VERSION ""

NS_ :

BS_:

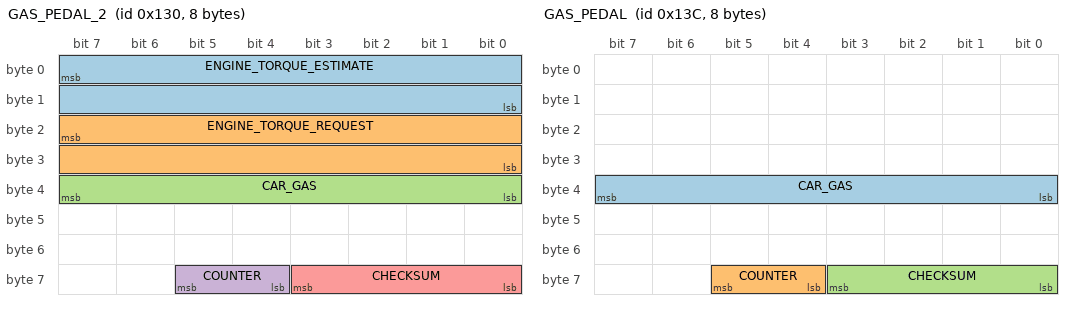
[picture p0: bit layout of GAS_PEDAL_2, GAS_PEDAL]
BO_ 304 GAS_PEDAL_2: 8 PCM
 SG_ ENGINE_TORQUE_ESTIMATE : 7|16@0- (1,0) [-1000|1000] "Nm" EON
 SG_ ENGINE_TORQUE_REQUEST : 23|16@0- (1,0) [-1000|1000] "Nm" EON
 SG_ CAR_GAS : 39|8@0+ (1,0) [0|255] "" EON
 SG_ COUNTER : 61|2@0+ (1,0) [0|3] "" EON
 SG_ CHECKSUM : 59|4@0+ (1,0) [0|15] "" EON

BO_ 316 GAS_PEDAL: 8 PCM
 SG_ CAR_GAS : 39|8@0+ (1,0) [0|255] "" EON
 SG_ COUNTER : 61|2@0+ (1,0) [0|3] "" EON
 SG_ CHECKSUM : 59|4@0+ (1,0) [0|15] "" EON

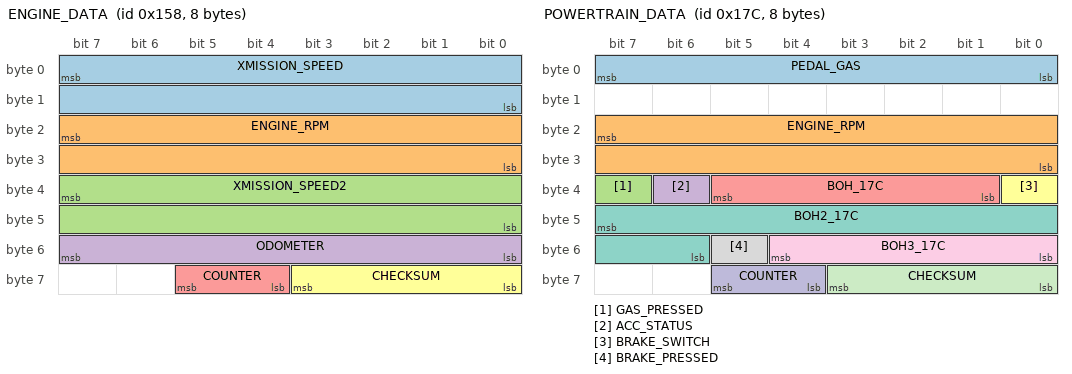
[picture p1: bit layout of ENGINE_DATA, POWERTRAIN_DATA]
BO_ 344 ENGINE_DATA: 8 PCM
 SG_ XMISSION_SPEED : 7|16@0+ (0.01,0) [0|250] "kph" EON
 SG_ ENGINE_RPM : 23|16@0+ (1,0) [0|15000] "rpm" EON
 SG_ XMISSION_SPEED2 : 39|16@0+ (0.01,0) [0|250] "kph" EON
 SG_ ODOMETER : 55|8@0+ (10,0) [0|2550] "m" XXX
 SG_ COUNTER : 61|2@0+ (1,0) [0|3] "" EON
 SG_ CHECKSUM : 59|4@0+ (1,0) [0|15] "" EON

BO_ 380 POWERTRAIN_DATA: 8 PCM
 SG_ PEDAL_GAS : 7|8@0+ (1,0) [0|255] "" EON
 SG_ ENGINE_RPM : 23|16@0+ (1,0) [0|15000] "rpm" EON
 SG_ GAS_PRESSED : 39|1@0+ (1,0) [0|1] "" EON
 SG_ ACC_STATUS : 38|1@0+ (1,0) [0|1] "" EON
 SG_ BOH_17C : 37|5@0+ (1,0) [0|1] "" EON
 SG_ BRAKE_SWITCH : 32|1@0+ (1,0) [0|1] "" EON
 SG_ BOH2_17C : 47|10@0+ (1,0) [0|1] "" EON
 SG_ BRAKE_PRESSED : 53|1@0+ (1,0) [0|1] "" EON
 SG_ BOH3_17C : 52|5@0+ (1,0) [0|1] "" EON
 SG_ COUNTER : 61|2@0+ (1,0) [0|3] "" EON
 SG_ CHECKSUM : 59|4@0+ (1,0) [0|15] "" EON

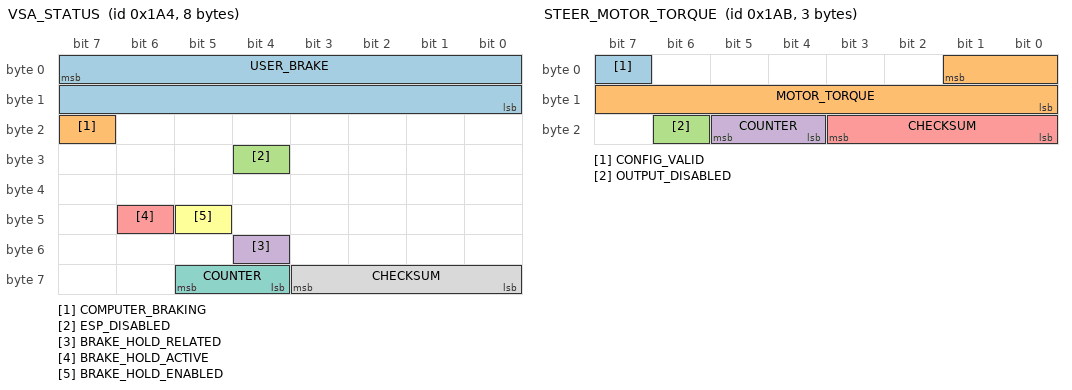
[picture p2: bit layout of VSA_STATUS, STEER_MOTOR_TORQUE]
BO_ 420 VSA_STATUS: 8 VSA
 SG_ USER_BRAKE : 7|16@0+ (0.015625,-1.609375) [0|1000] "" EON
 SG_ COMPUTER_BRAKING : 23|1@0+ (1,0) [0|1] "" EON
 SG_ ESP_DISABLED : 28|1@0+ (1,0) [0|1] "" EON
 SG_ BRAKE_HOLD_RELATED : 52|1@0+ (1,0) [0|1] "" XXX
 SG_ BRAKE_HOLD_ACTIVE : 46|1@0+ (1,0) [0|1] "" EON
 SG_ BRAKE_HOLD_ENABLED : 45|1@0+ (1,0) [0|1] "" EON
 SG_ COUNTER : 61|2@0+ (1,0) [0|3] "" EON
 SG_ CHECKSUM : 59|4@0+ (1,0) [0|15] "" EON

BO_ 427 STEER_MOTOR_TORQUE: 3 EPS
 SG_ CONFIG_VALID : 7|1@0+ (1,0) [0|1] "" EON
 SG_ MOTOR_TORQUE : 1|10@0+ (1,0) [0|256] "" EON
 SG_ OUTPUT_DISABLED : 22|1@0+ (1,0) [0|1] "" EON
 SG_ COUNTER : 21|2@0+ (1,0) [0|3] "" EON
 SG_ CHECKSUM : 19|4@0+ (1,0) [0|15] "" EON

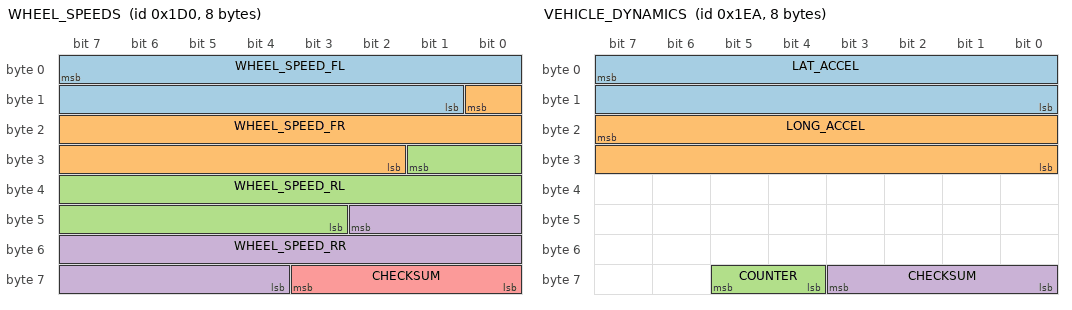
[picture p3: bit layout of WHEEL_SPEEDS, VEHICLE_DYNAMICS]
BO_ 464 WHEEL_SPEEDS: 8 VSA
 SG_ WHEEL_SPEED_FL : 7|15@0+ (0.01,0) [0|250] "kph" EON
 SG_ WHEEL_SPEED_FR : 8|15@0+ (0.01,0) [0|250] "kph" EON
 SG_ WHEEL_SPEED_RL : 25|15@0+ (0.01,0) [0|250] "kph" EON
 SG_ WHEEL_SPEED_RR : 42|15@0+ (0.01,0) [0|250] "kph" EON
 SG_ CHECKSUM : 59|4@0+ (1,0) [0|3] "" EON

BO_ 490 VEHICLE_DYNAMICS: 8 VSA
 SG_ LAT_ACCEL : 7|16@0- (0.0015,0) [-20|20] "m/s2" EON
 SG_ LONG_ACCEL : 23|16@0- (0.0015,0) [-20|20] "m/s2" EON
 SG_ COUNTER : 61|2@0+ (1,0) [0|3] "" EON
 SG_ CHECKSUM : 59|4@0+ (1,0) [0|3] "" EON

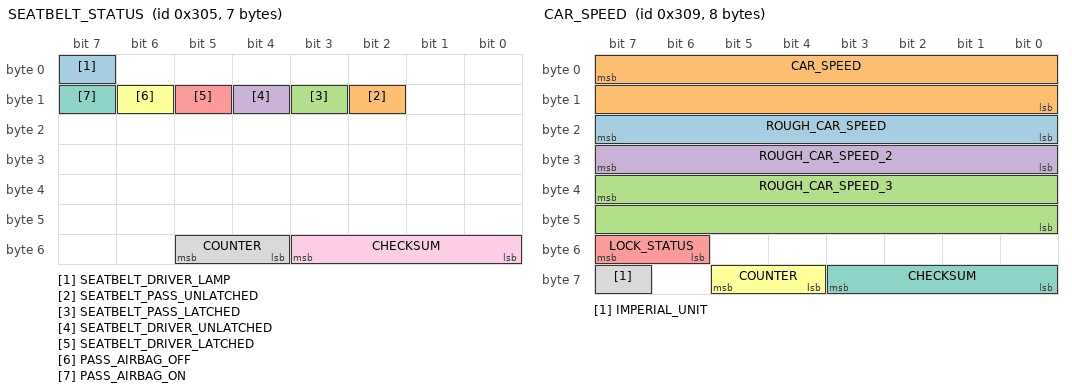
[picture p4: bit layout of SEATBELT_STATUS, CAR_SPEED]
BO_ 773 SEATBELT_STATUS: 7 BDY
 SG_ SEATBELT_DRIVER_LAMP : 7|1@0+ (1,0) [0|1] "" EON
 SG_ SEATBELT_PASS_UNLATCHED : 10|1@0+ (1,0) [0|1] "" EON
 SG_ SEATBELT_PASS_LATCHED : 11|1@0+ (1,0) [0|1] "" EON
 SG_ SEATBELT_DRIVER_UNLATCHED : 12|1@0+ (1,0) [0|1] "" EON
 SG_ SEATBELT_DRIVER_LATCHED : 13|1@0+ (1,0) [0|1] "" EON
 SG_ PASS_AIRBAG_OFF : 14|1@0+ (1,0) [0|1] "" EON
 SG_ PASS_AIRBAG_ON : 15|1@0+ (1,0) [0|1] "" EON
 SG_ COUNTER : 53|2@0+ (1,0) [0|3] "" EON
 SG_ CHECKSUM : 51|4@0+ (1,0) [0|3] "" EON

BO_ 777 CAR_SPEED: 8 PCM
 SG_ ROUGH_CAR_SPEED : 23|8@0+ (1,0) [0|255] "mph" XXX
 SG_ CAR_SPEED : 7|16@0+ (0.01,0) [0|65535] "kph" XXX
 SG_ ROUGH_CAR_SPEED_3 : 39|16@0+ (0.01,0) [0|65535] "kph" XXX
 SG_ ROUGH_CAR_SPEED_2 : 31|8@0+ (1,0) [0|255] "mph" XXX
 SG_ LOCK_STATUS : 55|2@0+ (1,0) [0|255] "" XXX
 SG_ COUNTER : 61|2@0+ (1,0) [0|3] "" XXX
 SG_ CHECKSUM : 59|4@0+ (1,0) [0|15] "" XXX
 SG_ IMPERIAL_UNIT : 63|1@0+ (1,0) [0|1] "" XXX

BO_ 780 ACC_HUD: 8 ADAS
 SG_ PCM_SPEED : 7|16@0+ (0.01,0) [0|250] "kph" BDY
 SG_ PCM_GAS : 23|8@0+ (1,0) [0|127] "" BDY
 SG_ CRUISE_SPEED : 31|8@0+ (1,0) [0|255] "kph" BDY
 SG_ DTC_MODE : 39|1@0+ (1,0) [0|1] "" BDY
 SG_ BOH : 38|1@0+ (1,0) [0|1] "" BDY
 SG_ ACC_PROBLEM : 37|1@0+ (1,0) [0|1] "" BDY
 SG_ FCM_OFF : 35|1@0+ (1,0) [0|1] "" BDY
 SG_ FCM_OFF_2 : 36|1@0+ (1,0) [0|1] "" BDY
 SG_ FCM_PROBLEM : 34|1@0+ (1,0) [0|1] "" BDY
 SG_ RADAR_OBSTRUCTED : 33|1@0+ (1,0) [0|1] "" BDY
 SG_ ENABLE_MINI_CAR : 32|1@0+ (1,0) [0|1] "" BDY
 SG_ HUD_DISTANCE : 47|2@0+ (1,0) [0|3] "" BDY
 SG_ HUD_LEAD : 45|2@0+ (1,0) [0|3] "" BDY
 SG_ BOH_3 : 43|1@0+ (1,0) [0|3] "" BDY
 SG_ BOH_4 : 42|1@0+ (1,0) [0|3] "" BDY
 SG_ BOH_5 : 41|1@0+ (1,0) [0|3] "" BDY
 SG_ CRUISE_CONTROL_LABEL : 40|1@0+ (1,0) [0|3] "" BDY
 SG_ SET_ME_X01_2 : 55|1@0+ (1,0) [0|1] "" BDY
 SG_ IMPERIAL_UNIT : 54|1@0+ (1,0) [0|1] "" BDY
 SG_ ACC_ON : 52|1@0+ (1,0) [0|1] "" BDY
 SG_ CHIME : 51|3@0+ (1,0) [0|1] "" BDY
 SG_ SET_ME_X01 : 48|1@0+ (1,0) [0|1] "" BDY
 SG_ ICONS : 63|2@0+ (1,0) [0|1] "" BDY
 SG_ COUNTER : 61|2@0+ (1,0) [0|3] "" BDY
 SG_ CHECKSUM : 59|4@0+ (1,0) [0|3] "" BDY

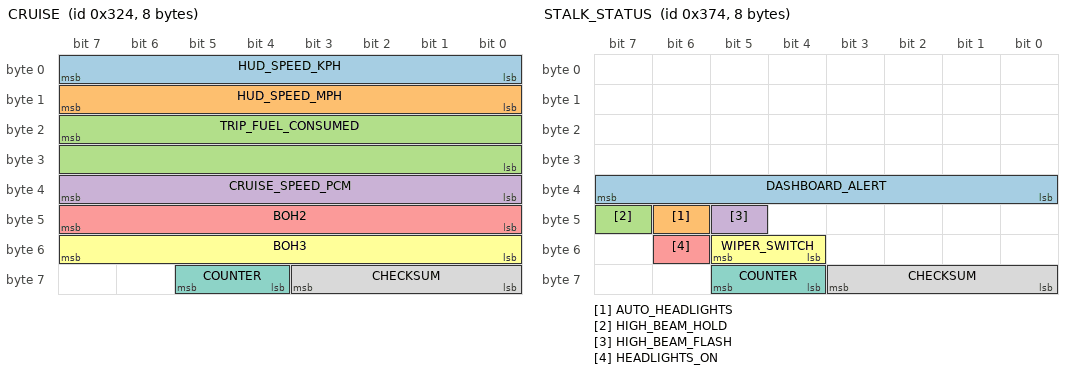
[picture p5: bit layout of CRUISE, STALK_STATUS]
BO_ 804 CRUISE: 8 PCM
 SG_ HUD_SPEED_KPH : 7|8@0+ (1,0) [0|255] "kph" EON
 SG_ HUD_SPEED_MPH : 15|8@0+ (1,0) [0|255] "mph" EON
 SG_ TRIP_FUEL_CONSUMED : 23|16@0+ (1,0) [0|255] "" EON
 SG_ CRUISE_SPEED_PCM : 39|8@0+ (1,0) [0|255] "" EON
 SG_ BOH2 : 47|8@0- (1,0) [0|255] "" EON
 SG_ BOH3 : 55|8@0+ (1,0) [0|255] "" EON
 SG_ COUNTER : 61|2@0+ (1,0) [0|3] "" EON
 SG_ CHECKSUM : 59|4@0+ (1,0) [0|15] "" EON

BO_ 884 STALK_STATUS: 8 XXX
 SG_ DASHBOARD_ALERT : 39|8@0+ (1,0) [0|255] "" EON
 SG_ AUTO_HEADLIGHTS : 46|1@0+ (1,0) [0|1] "" EON
 SG_ HIGH_BEAM_HOLD : 47|1@0+ (1,0) [0|1] "" EON
 SG_ HIGH_BEAM_FLASH : 45|1@0+ (1,0) [0|1] "" EON
 SG_ HEADLIGHTS_ON : 54|1@0+ (1,0) [0|1] "" EON
 SG_ WIPER_SWITCH : 53|2@0+ (1,0) [0|3] "" XXX
 SG_ COUNTER : 61|2@0+ (1,0) [0|3] "" EON
 SG_ CHECKSUM : 59|4@0+ (1,0) [0|15] "" EON

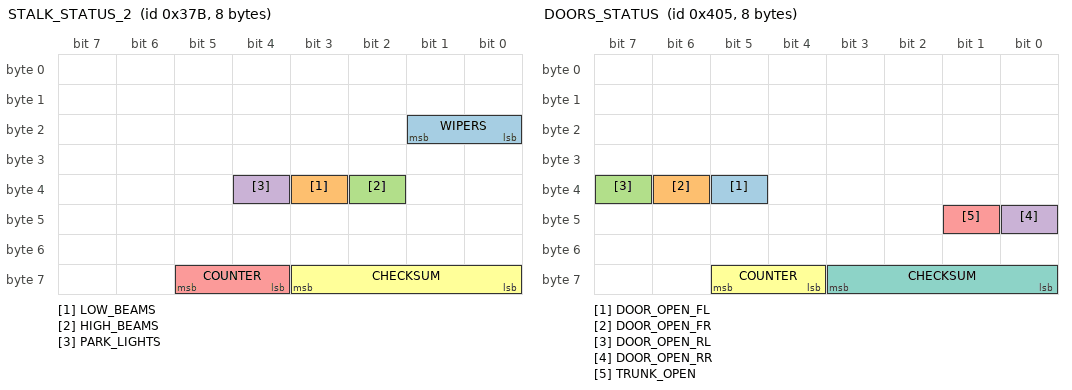
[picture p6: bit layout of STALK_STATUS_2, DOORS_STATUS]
BO_ 891 STALK_STATUS_2: 8 XXX
 SG_ WIPERS : 17|2@0+ (1,0) [0|3] "" EON
 SG_ LOW_BEAMS : 35|1@0+ (1,0) [0|1] "" XXX
 SG_ HIGH_BEAMS : 34|1@0+ (1,0) [0|1] "" XXX
 SG_ PARK_LIGHTS : 36|1@0+ (1,0) [0|1] "" XXX
 SG_ COUNTER : 61|2@0+ (1,0) [0|3] "" EON
 SG_ CHECKSUM : 59|4@0+ (1,0) [0|15] "" EON

BO_ 1029 DOORS_STATUS: 8 BDY
 SG_ DOOR_OPEN_FL : 37|1@0+ (1,0) [0|1] "" EON
 SG_ DOOR_OPEN_FR : 38|1@0+ (1,0) [0|1] "" EON
 SG_ DOOR_OPEN_RL : 39|1@0+ (1,0) [0|1] "" EON
 SG_ DOOR_OPEN_RR : 40|1@0+ (1,0) [0|1] "" EON
 SG_ TRUNK_OPEN : 41|1@0+ (1,0) [0|1] "" EON
 SG_ COUNTER : 61|2@0+ (1,0) [0|3] "" EON
 SG_ CHECKSUM : 59|4@0+ (1,0) [0|15] "" EON

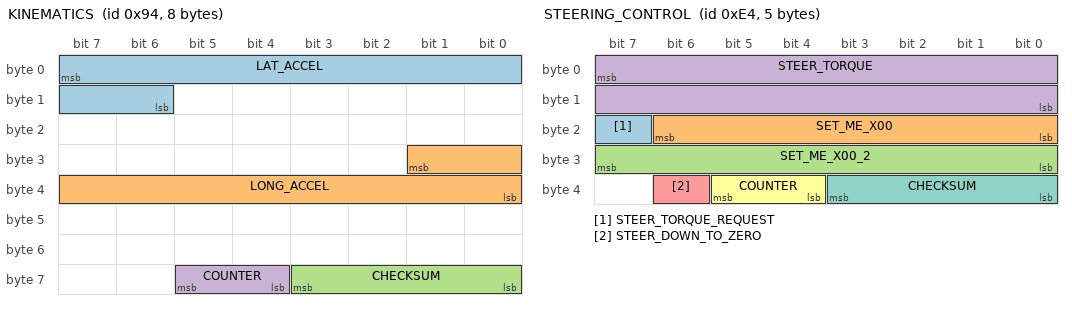
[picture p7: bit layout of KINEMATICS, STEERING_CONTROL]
BO_ 148 KINEMATICS: 8 XXX
 SG_ LAT_ACCEL : 7|10@0+ (-0.035,17.92) [-20|20] "m/s2" EON
 SG_ LONG_ACCEL : 25|10@0+ (-0.035,17.92) [-20|20] "m/s2" EON
 SG_ CHECKSUM : 59|4@0+ (1,0) [0|3] "" EON
 SG_ COUNTER : 61|2@0+ (1,0) [0|3] "" EON

BO_ 228 STEERING_CONTROL: 5 EON
 SG_ STEER_TORQUE_REQUEST : 23|1@0+ (1,0) [0|1] "" EPS
 SG_ SET_ME_X00 : 22|7@0+ (1,0) [0|127] "" EPS
 SG_ SET_ME_X00_2 : 31|8@0+ (1,0) [0|0] "" EPS
 SG_ STEER_TORQUE : 7|16@0- (1,0) [-4096|4096] "" EPS
 SG_ STEER_DOWN_TO_ZERO : 38|1@0+ (1,0) [0|1] "" EPS
 SG_ COUNTER : 37|2@0+ (1,0) [0|3] "" EPS
 SG_ CHECKSUM : 35|4@0+ (1,0) [0|15] "" EPS

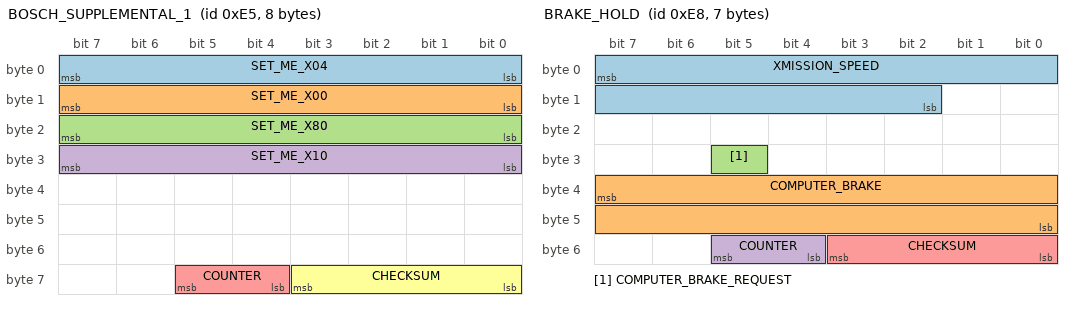
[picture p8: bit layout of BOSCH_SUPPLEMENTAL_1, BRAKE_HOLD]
BO_ 229 BOSCH_SUPPLEMENTAL_1: 8 XXX
 SG_ SET_ME_X04 : 0|8@1+ (1,0) [0|255] "" XXX
 SG_ SET_ME_X00 : 8|8@1+ (1,0) [0|255] "" XXX
 SG_ SET_ME_X80 : 16|8@1+ (1,0) [0|255] "" XXX
 SG_ SET_ME_X10 : 24|8@1+ (1,0) [0|255] "" XXX
 SG_ COUNTER : 61|2@0+ (1,0) [0|3] "" XXX
 SG_ CHECKSUM : 59|4@0+ (1,0) [0|15] "" XXX

BO_ 232 BRAKE_HOLD: 7 XXX
 SG_ XMISSION_SPEED : 7|14@0- (1,0) [1|0] "" XXX
 SG_ COMPUTER_BRAKE : 39|16@0+ (1,0) [0|0] "" XXX
 SG_ COMPUTER_BRAKE_REQUEST : 29|1@0+ (1,0) [0|0] "" XXX
 SG_ COUNTER : 53|2@0+ (1,0) [0|3] "" XXX
 SG_ CHECKSUM : 51|4@0+ (1,0) [0|15] "" XXX

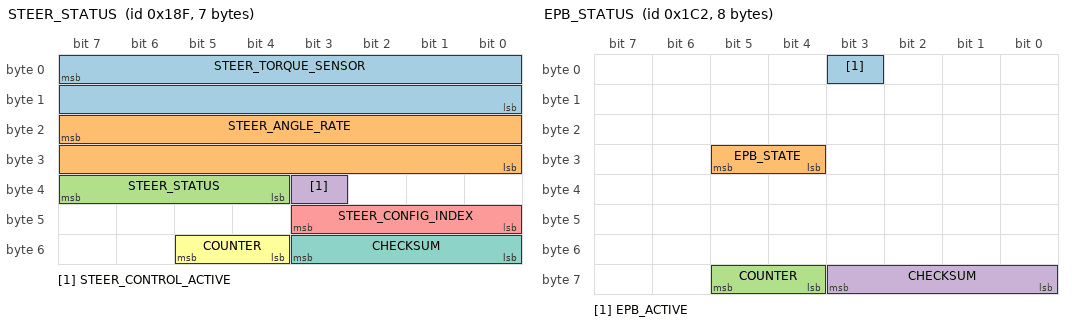
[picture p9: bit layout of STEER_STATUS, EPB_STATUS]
BO_ 399 STEER_STATUS: 7 EPS
 SG_ STEER_TORQUE_SENSOR : 7|16@0- (-1,0) [-31000|31000] "tbd" EON
 SG_ STEER_ANGLE_RATE : 23|16@0- (-0.1,0) [-31000|31000] "deg/s" EON
 SG_ STEER_STATUS : 39|4@0+ (1,0) [0|15] "" EON
 SG_ STEER_CONTROL_ACTIVE : 35|1@0+ (1,0) [0|1] "" EON
 SG_ STEER_CONFIG_INDEX : 43|4@0+ (1,0) [0|15] "" EON
 SG_ COUNTER : 53|2@0+ (1,0) [0|3] "" EON
 SG_ CHECKSUM : 51|4@0+ (1,0) [0|15] "" EON

BO_ 450 EPB_STATUS: 8 EPB
 SG_ EPB_ACTIVE : 3|1@0+ (1,0) [0|1] "" EON
 SG_ EPB_STATE : 29|2@0+ (1,0) [0|3] "" EON
 SG_ COUNTER : 61|2@0+ (1,0) [0|3] "" XXX
 SG_ CHECKSUM : 59|4@0+ (1,0) [0|15] "" XXX

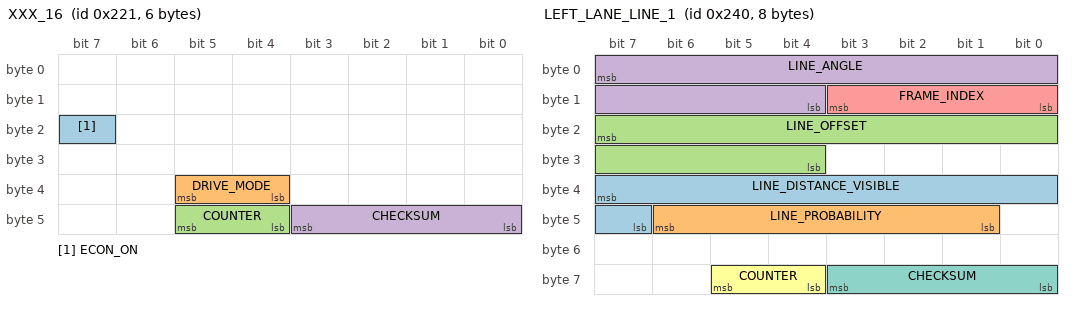
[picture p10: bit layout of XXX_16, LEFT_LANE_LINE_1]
BO_ 545 XXX_16: 6 SCM
 SG_ ECON_ON : 23|1@0+ (1,0) [0|1] "" XXX
 SG_ DRIVE_MODE : 37|2@0+ (1,0) [0|3] "" XXX
 SG_ COUNTER : 45|2@0+ (1,0) [0|3] "" BDY
 SG_ CHECKSUM : 43|4@0+ (1,0) [0|15] "" BDY

BO_ 576 LEFT_LANE_LINE_1: 8 CAM
 SG_ LINE_DISTANCE_VISIBLE : 39|9@0+ (1,0) [0|1] "" XXX
 SG_ LINE_PROBABILITY : 46|6@0+ (0.015625,0) [0|1] "" XXX
 SG_ LINE_OFFSET : 23|12@0+ (0.004,-8.192) [0|1] "Meters" XXX
 SG_ LINE_ANGLE : 7|12@0+ (0.0005,-1.024) [0|1] "" XXX
 SG_ FRAME_INDEX : 8|4@1+ (1,0) [0|15] "" XXX
 SG_ COUNTER : 61|2@0+ (1,0) [0|1] "" XXX
 SG_ CHECKSUM : 59|4@0+ (1,0) [0|1] "" XXX

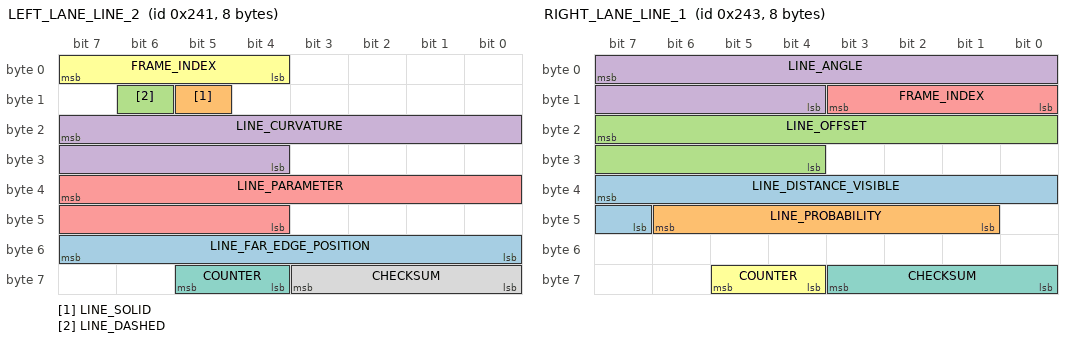
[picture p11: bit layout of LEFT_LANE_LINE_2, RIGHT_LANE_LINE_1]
BO_ 577 LEFT_LANE_LINE_2: 8 CAM
 SG_ LINE_FAR_EDGE_POSITION : 55|8@0+ (1,-128) [0|1] "" XXX
 SG_ LINE_SOLID : 13|1@0+ (1,0) [0|1] "" XXX
 SG_ LINE_DASHED : 14|1@0+ (1,0) [0|1] "" XXX
 SG_ LINE_CURVATURE : 23|12@0+ (0.00001,-0.02048) [0|1] "" XXX
 SG_ LINE_PARAMETER : 39|12@0+ (1,0) [0|1] "" XXX
 SG_ FRAME_INDEX : 7|4@0+ (1,0) [0|15] "" XXX
 SG_ COUNTER : 61|2@0+ (1,0) [0|1] "" XXX
 SG_ CHECKSUM : 59|4@0+ (1,0) [0|1] "" XXX

BO_ 579 RIGHT_LANE_LINE_1: 8 CAM
 SG_ LINE_DISTANCE_VISIBLE : 39|9@0+ (1,0) [0|1] "" XXX
 SG_ LINE_PROBABILITY : 46|6@0+ (0.015625,0) [0|1] "" XXX
 SG_ LINE_OFFSET : 23|12@0+ (0.004,-8.192) [0|1] "Meters" XXX
 SG_ LINE_ANGLE : 7|12@0+ (0.0005,-1.024) [0|1] "" XXX
 SG_ FRAME_INDEX : 8|4@1+ (1,0) [0|15] "" XXX
 SG_ COUNTER : 61|2@0+ (1,0) [0|1] "" XXX
 SG_ CHECKSUM : 59|4@0+ (1,0) [0|1] "" XXX

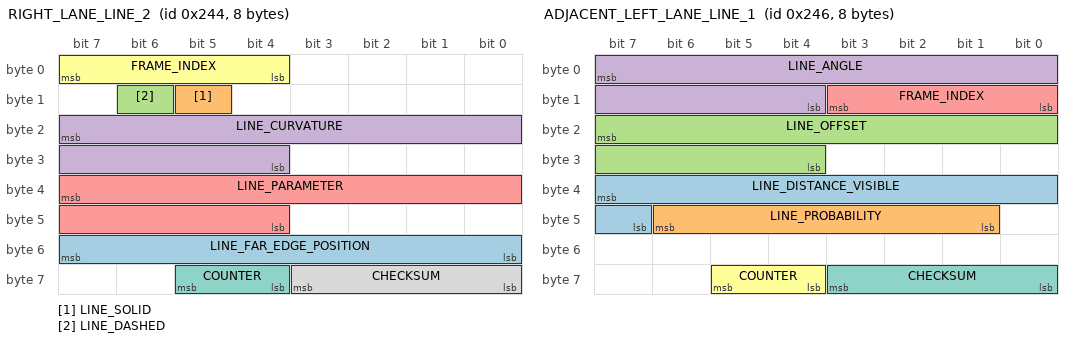
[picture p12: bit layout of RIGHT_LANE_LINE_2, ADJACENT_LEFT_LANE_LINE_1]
BO_ 580 RIGHT_LANE_LINE_2: 8 CAM
 SG_ LINE_FAR_EDGE_POSITION : 55|8@0+ (1,-128) [0|1] "" XXX
 SG_ LINE_SOLID : 13|1@0+ (1,0) [0|1] "" XXX
 SG_ LINE_DASHED : 14|1@0+ (1,0) [0|1] "" XXX
 SG_ LINE_CURVATURE : 23|12@0+ (0.00001,-0.02048) [0|1] "" XXX
 SG_ LINE_PARAMETER : 39|12@0+ (1,0) [0|1] "" XXX
 SG_ FRAME_INDEX : 7|4@0+ (1,0) [0|15] "" XXX
 SG_ COUNTER : 61|2@0+ (1,0) [0|1] "" XXX
 SG_ CHECKSUM : 59|4@0+ (1,0) [0|1] "" XXX

BO_ 582 ADJACENT_LEFT_LANE_LINE_1: 8 CAM
 SG_ LINE_DISTANCE_VISIBLE : 39|9@0+ (1,0) [0|1] "" XXX
 SG_ LINE_PROBABILITY : 46|6@0+ (0.015625,0) [0|1] "" XXX
 SG_ LINE_OFFSET : 23|12@0+ (0.004,-8.192) [0|1] "Meters" XXX
 SG_ LINE_ANGLE : 7|12@0+ (0.0005,-1.024) [0|1] "" XXX
 SG_ FRAME_INDEX : 8|4@1+ (1,0) [0|15] "" XXX
 SG_ COUNTER : 61|2@0+ (1,0) [0|1] "" XXX
 SG_ CHECKSUM : 59|4@0+ (1,0) [0|1] "" XXX

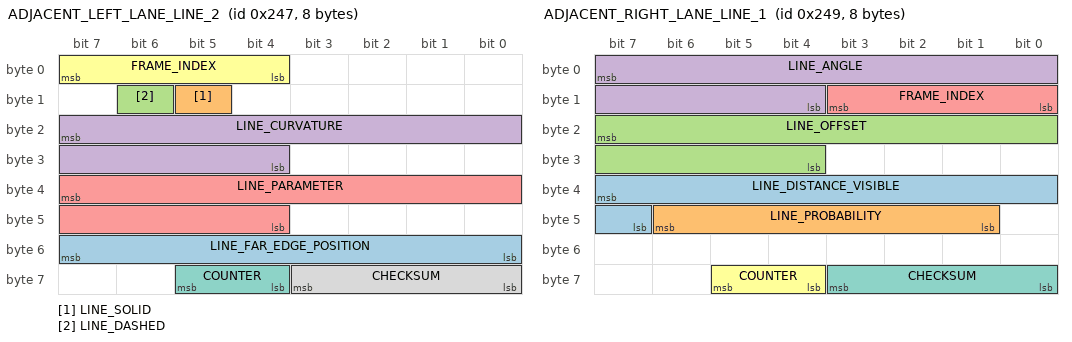
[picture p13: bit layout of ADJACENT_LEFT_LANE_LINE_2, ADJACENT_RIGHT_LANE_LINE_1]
BO_ 583 ADJACENT_LEFT_LANE_LINE_2: 8 CAM
 SG_ LINE_FAR_EDGE_POSITION : 55|8@0+ (1,-128) [0|1] "" XXX
 SG_ LINE_SOLID : 13|1@0+ (1,0) [0|1] "" XXX
 SG_ LINE_DASHED : 14|1@0+ (1,0) [0|1] "" XXX
 SG_ LINE_CURVATURE : 23|12@0+ (0.00001,-0.02048) [0|1] "" XXX
 SG_ LINE_PARAMETER : 39|12@0+ (1,0) [0|1] "" XXX
 SG_ FRAME_INDEX : 7|4@0+ (1,0) [0|15] "" XXX
 SG_ COUNTER : 61|2@0+ (1,0) [0|1] "" XXX
 SG_ CHECKSUM : 59|4@0+ (1,0) [0|1] "" XXX

BO_ 585 ADJACENT_RIGHT_LANE_LINE_1: 8 CAM
 SG_ LINE_DISTANCE_VISIBLE : 39|9@0+ (1,0) [0|1] "" XXX
 SG_ LINE_PROBABILITY : 46|6@0+ (0.015625,0) [0|1] "" XXX
 SG_ LINE_OFFSET : 23|12@0+ (0.004,-8.192) [0|1] "Meters" XXX
 SG_ LINE_ANGLE : 7|12@0+ (0.0005,-1.024) [0|1] "" XXX
 SG_ FRAME_INDEX : 8|4@1+ (1,0) [0|15] "" XXX
 SG_ COUNTER : 61|2@0+ (1,0) [0|1] "" XXX
 SG_ CHECKSUM : 59|4@0+ (1,0) [0|1] "" XXX

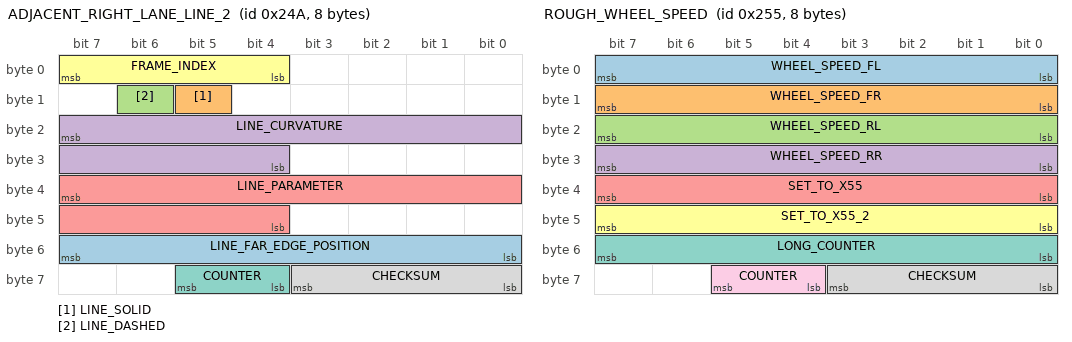
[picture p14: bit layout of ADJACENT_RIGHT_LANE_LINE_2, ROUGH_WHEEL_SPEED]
BO_ 586 ADJACENT_RIGHT_LANE_LINE_2: 8 CAM
 SG_ LINE_FAR_EDGE_POSITION : 55|8@0+ (1,-128) [0|1] "" XXX
 SG_ LINE_SOLID : 13|1@0+ (1,0) [0|1] "" XXX
 SG_ LINE_DASHED : 14|1@0+ (1,0) [0|1] "" XXX
 SG_ LINE_CURVATURE : 23|12@0+ (0.00001,-0.02048) [0|1] "" XXX
 SG_ LINE_PARAMETER : 39|12@0+ (1,0) [0|1] "" XXX
 SG_ FRAME_INDEX : 7|4@0+ (1,0) [0|15] "" XXX
 SG_ COUNTER : 61|2@0+ (1,0) [0|1] "" XXX
 SG_ CHECKSUM : 59|4@0+ (1,0) [0|1] "" XXX

BO_ 597 ROUGH_WHEEL_SPEED: 8 VSA
 SG_ WHEEL_SPEED_FL : 7|8@0+ (1,0) [0|255] "mph" EON
 SG_ WHEEL_SPEED_FR : 15|8@0+ (1,0) [0|255] "mph" EON
 SG_ WHEEL_SPEED_RL : 23|8@0+ (1,0) [0|255] "mph" EON
 SG_ WHEEL_SPEED_RR : 31|8@0+ (1,0) [0|255] "mph" EON
 SG_ SET_TO_X55 : 39|8@0+ (1,0) [0|255] "" XXX
 SG_ SET_TO_X55_2 : 47|8@0+ (1,0) [0|255] "" EON
 SG_ LONG_COUNTER : 55|8@0+ (1,0) [0|255] "" XXX
 SG_ CHECKSUM : 59|4@0+ (1,0) [0|15] "" XXX
 SG_ COUNTER : 61|2@0+ (1,0) [0|3] "" XXX

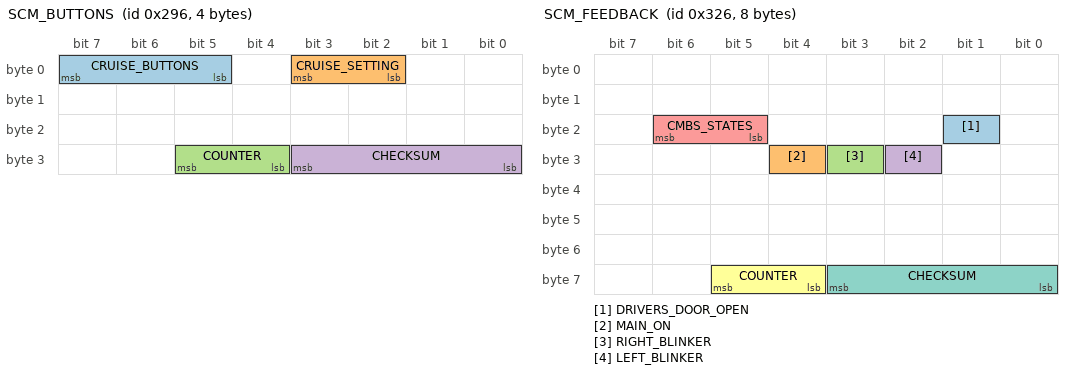
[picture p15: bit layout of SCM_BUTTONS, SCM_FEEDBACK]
BO_ 662 SCM_BUTTONS: 4 SCM
 SG_ CRUISE_BUTTONS : 7|3@0+ (1,0) [0|7] "" EON
 SG_ CRUISE_SETTING : 3|2@0+ (1,0) [0|3] "" EON
 SG_ COUNTER : 29|2@0+ (1,0) [0|3] "" EON
 SG_ CHECKSUM : 27|4@0+ (1,0) [0|15] "" EON

BO_ 806 SCM_FEEDBACK: 8 SCM
 SG_ DRIVERS_DOOR_OPEN : 17|1@0+ (1,0) [0|1] "" XXX
 SG_ MAIN_ON : 28|1@0+ (1,0) [0|1] "" EON
 SG_ RIGHT_BLINKER : 27|1@0+ (1,0) [0|1] "" EON
 SG_ LEFT_BLINKER : 26|1@0+ (1,0) [0|1] "" EON
 SG_ CMBS_STATES : 22|2@0+ (1,0) [0|3] "" EON
 SG_ COUNTER : 61|2@0+ (1,0) [0|3] "" XXX
 SG_ CHECKSUM : 59|4@0+ (1,0) [0|15] "" XXX

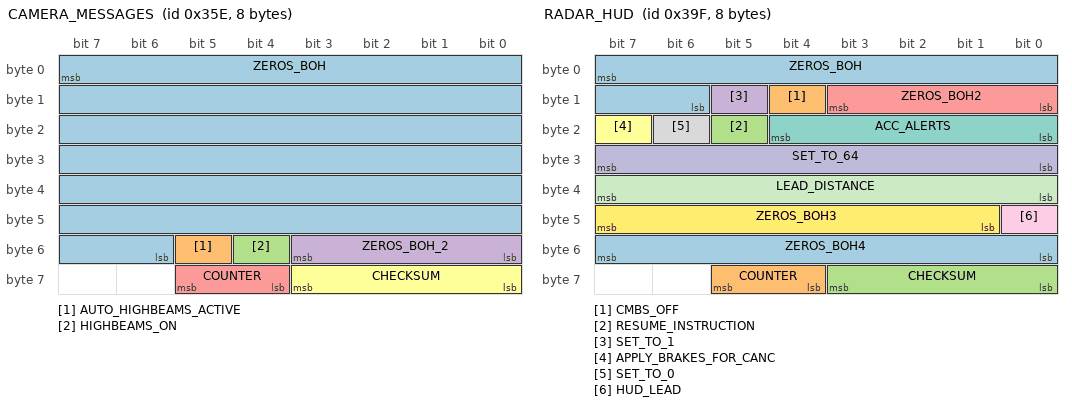
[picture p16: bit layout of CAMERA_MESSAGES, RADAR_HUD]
BO_ 862 CAMERA_MESSAGES: 8 CAM
 SG_ ZEROS_BOH : 7|50@0+ (1,0) [0|127] "" BDY
 SG_ AUTO_HIGHBEAMS_ACTIVE : 53|1@0+ (1,0) [0|1] "" XXX
 SG_ HIGHBEAMS_ON : 52|1@0+ (1,0) [0|1] "" XXX
 SG_ ZEROS_BOH_2 : 51|4@0+ (1,0) [0|15] "" XXX
 SG_ COUNTER : 61|2@0+ (1,0) [0|3] "" XXX
 SG_ CHECKSUM : 59|4@0+ (1,0) [0|15] "" XXX

BO_ 927 RADAR_HUD: 8 RADAR
 SG_ ZEROS_BOH : 7|10@0+ (1,0) [0|127] "" BDY
 SG_ CMBS_OFF : 12|1@0+ (1,0) [0|1] "" BDY
 SG_ RESUME_INSTRUCTION : 21|1@0+ (1,0) [0|1] "" XXX
 SG_ SET_TO_1 : 13|1@0+ (1,0) [0|1] "" BDY
 SG_ ZEROS_BOH2 : 11|4@0+ (1,0) [0|1] "" XXX
 SG_ APPLY_BRAKES_FOR_CANC : 23|1@0+ (1,0) [0|1] "" XXX
 SG_ ACC_ALERTS : 20|5@0+ (1,0) [0|1] "" BDY
 SG_ SET_TO_0 : 22|1@0+ (1,0) [0|1] "" XXX
 SG_ HUD_LEAD : 40|1@0+ (1,0) [0|1] "" XXX
 SG_ SET_TO_64 : 31|8@0+ (1,0) [0|255] "" XXX
 SG_ LEAD_DISTANCE : 39|8@0+ (1,0) [0|255] "" XXX
 SG_ ZEROS_BOH3 : 47|7@0+ (1,0) [0|127] "" XXX
 SG_ ZEROS_BOH4 : 55|8@0+ (1,0) [0|255] "" XXX
 SG_ COUNTER : 61|2@0+ (1,0) [0|3] "" XXX
 SG_ CHECKSUM : 59|4@0+ (1,0) [0|15] "" XXX

BO_ 13274 LKAS_HUD_A: 5 ADAS
 SG_ CAM_TEMP_HIGH : 7|1@0+ (1,0) [0|255] "" BDY
 SG_ SET_ME_X41 : 6|7@0+ (1,0) [0|127] "" BDY
 SG_ BOH : 6|7@0+ (1,0) [0|127] "" BDY
 SG_ DASHED_LANES : 14|1@0+ (1,0) [0|1] "" BDY
 SG_ DTC : 13|1@0+ (1,0) [0|1] "" BDY
 SG_ LKAS_PROBLEM : 12|1@0+ (1,0) [0|1] "" BDY
 SG_ LKAS_OFF : 11|1@0+ (1,0) [0|1] "" BDY
 SG_ SOLID_LANES : 10|1@0+ (1,0) [0|1] "" BDY
 SG_ LDW_RIGHT : 9|1@0+ (1,0) [0|1] "" BDY
 SG_ STEERING_REQUIRED : 8|1@0+ (1,0) [0|1] "" BDY
 SG_ BOH_2 : 23|2@0+ (1,0) [0|4] "" BDY
 SG_ LDW_PROBLEM : 21|1@0+ (1,0) [0|1] "" BDY
 SG_ BEEP : 17|2@0+ (1,0) [0|1] "" BDY
 SG_ SET_ME_X01 : 20|1@0+ (1,0) [0|1] "" BDY
 SG_ LDW_ON : 28|1@0+ (1,0) [0|1] "" BDY
 SG_ LDW_OFF : 27|1@0+ (1,0) [0|1] "" BDY
 SG_ CLEAN_WINDSHIELD : 26|1@0+ (1,0) [0|1] "" BDY
 SG_ COUNTER : 37|2@0+ (1,0) [0|3] "" BDY
 SG_ CHECKSUM : 35|4@0+ (1,0) [0|15] "" BDY

BO_ 13275 LKAS_HUD_B: 8 ADAS
 SG_ CAM_TEMP_HIGH : 7|1@0+ (1,0) [0|255] "" BDY
 SG_ SET_ME_X41 : 6|7@0+ (1,0) [0|127] "" BDY
 SG_ BOH : 6|7@0+ (1,0) [0|127] "" BDY
 SG_ DASHED_LANES : 14|1@0+ (1,0) [0|1] "" BDY
 SG_ DTC : 13|1@0+ (1,0) [0|1] "" BDY
 SG_ LKAS_PROBLEM : 12|1@0+ (1,0) [0|1] "" BDY
 SG_ LKAS_OFF : 11|1@0+ (1,0) [0|1] "" BDY
 SG_ SOLID_LANES : 10|1@0+ (1,0) [0|1] "" BDY
 SG_ LDW_RIGHT : 9|1@0+ (1,0) [0|1] "" BDY
 SG_ STEERING_REQUIRED : 8|1@0+ (1,0) [0|1] "" BDY
 SG_ BOH_2 : 23|2@0+ (1,0) [0|4] "" BDY
 SG_ LDW_PROBLEM : 21|1@0+ (1,0) [0|1] "" BDY
 SG_ BEEP : 17|2@0+ (1,0) [0|1] "" BDY
 SG_ SET_ME_X01 : 20|1@0+ (1,0) [0|1] "" BDY
 SG_ LDW_ON : 28|1@0+ (1,0) [0|1] "" BDY
 SG_ LDW_OFF : 27|1@0+ (1,0) [0|1] "" BDY
 SG_ CLEAN_WINDSHIELD : 26|1@0+ (1,0) [0|1] "" BDY
 SG_ COUNTER : 61|2@0+ (1,0) [0|3] "" BDY
 SG_ CHECKSUM : 59|4@0+ (1,0) [0|15] "" BDY

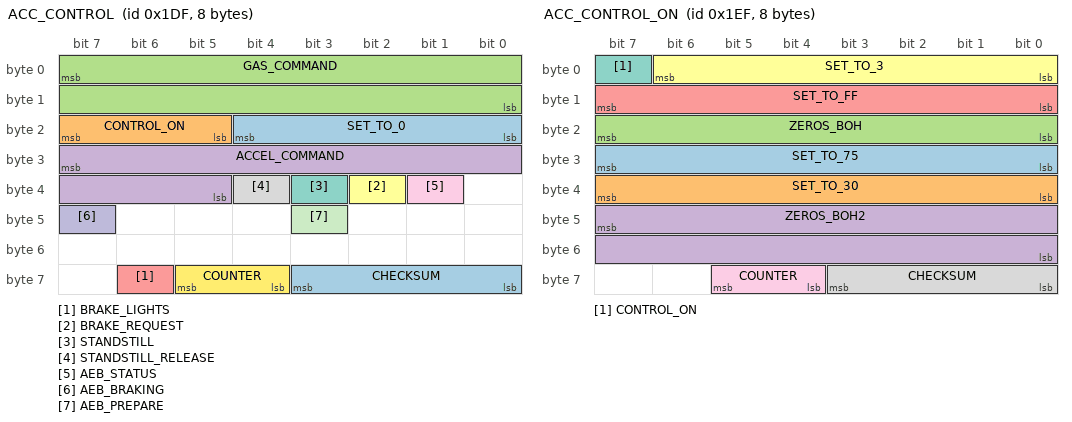
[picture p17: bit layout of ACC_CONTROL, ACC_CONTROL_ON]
BO_ 479 ACC_CONTROL: 8 EON
 SG_ SET_TO_0 : 20|5@0+ (1,0) [0|1] "" XXX
 SG_ CONTROL_ON : 23|3@0+ (1,0) [0|5] "" XXX
 SG_ GAS_COMMAND : 7|16@0- (1,0) [0|0] "" XXX
 SG_ ACCEL_COMMAND : 31|11@0- (0.01,0) [0|0] "m/s2" XXX
 SG_ BRAKE_LIGHTS : 62|1@0+ (1,0) [0|1] "" XXX
 SG_ BRAKE_REQUEST : 34|1@0+ (1,0) [0|1] "" XXX
 SG_ STANDSTILL : 35|1@0+ (1,0) [0|1] "" XXX
 SG_ STANDSTILL_RELEASE : 36|1@0+ (1,0) [0|1] "" XXX
 SG_ AEB_STATUS : 33|1@0+ (1,0) [0|1] "" XXX
 SG_ AEB_BRAKING : 47|1@0+ (1,0) [0|1] "" XXX
 SG_ AEB_PREPARE : 43|1@0+ (1,0) [0|1] "" XXX
 SG_ COUNTER : 61|2@0+ (1,0) [0|3] "" XXX
 SG_ CHECKSUM : 59|4@0+ (1,0) [0|15] "" XXX

BO_ 495 ACC_CONTROL_ON: 8 XXX
 SG_ SET_TO_75 : 31|8@0+ (1,0) [0|255] "" XXX
 SG_ SET_TO_30 : 39|8@0+ (1,0) [0|255] "" XXX
 SG_ ZEROS_BOH : 23|8@0+ (1,0) [0|255] "" XXX
 SG_ ZEROS_BOH2 : 47|16@0+ (1,0) [0|255] "" XXX
 SG_ SET_TO_FF : 15|8@0+ (1,0) [0|255] "" XXX
 SG_ SET_TO_3 : 6|7@0+ (1,0) [0|4095] "" XXX
 SG_ CONTROL_ON : 7|1@0+ (1,0) [0|1] "" XXX
 SG_ CHECKSUM : 59|4@0+ (1,0) [0|15] "" XXX
 SG_ COUNTER : 61|2@0+ (1,0) [0|3] "" XXX

BO_ 829 LKAS_HUD: 5 ADAS
 SG_ CAM_TEMP_HIGH : 7|1@0+ (1,0) [0|255] "" BDY
 SG_ SET_ME_X41 : 6|7@0+ (1,0) [0|127] "" BDY
 SG_ BOH : 6|7@0+ (1,0) [0|127] "" BDY
 SG_ DASHED_LANES : 14|1@0+ (1,0) [0|1] "" BDY
 SG_ DTC : 13|1@0+ (1,0) [0|1] "" BDY
 SG_ LKAS_PROBLEM : 12|1@0+ (1,0) [0|1] "" BDY
 SG_ LKAS_OFF : 11|1@0+ (1,0) [0|1] "" BDY
 SG_ SOLID_LANES : 10|1@0+ (1,0) [0|1] "" BDY
 SG_ LDW_RIGHT : 9|1@0+ (1,0) [0|1] "" BDY
 SG_ STEERING_REQUIRED : 8|1@0+ (1,0) [0|1] "" BDY
 SG_ BOH_2 : 23|2@0+ (1,0) [0|4] "" BDY
 SG_ LDW_PROBLEM : 21|1@0+ (1,0) [0|1] "" BDY
 SG_ BEEP : 17|2@0+ (1,0) [0|1] "" BDY
 SG_ LDW_ON : 28|1@0+ (1,0) [0|1] "" BDY
 SG_ LDW_OFF : 27|1@0+ (1,0) [0|1] "" BDY
 SG_ CLEAN_WINDSHIELD : 26|1@0+ (1,0) [0|1] "" BDY
 SG_ SET_ME_X48 : 31|8@0+ (1,0) [0|255] "" BDY
 SG_ COUNTER : 37|2@0+ (1,0) [0|3] "" BDY
 SG_ CHECKSUM : 35|4@0+ (1,0) [0|15] "" BDY

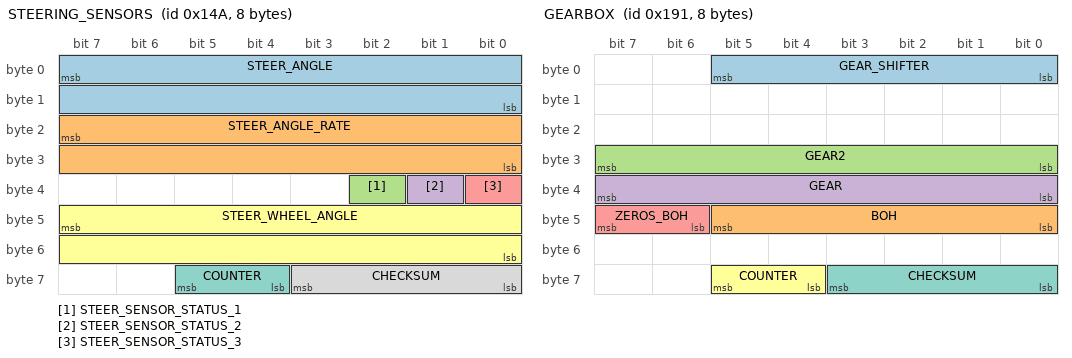
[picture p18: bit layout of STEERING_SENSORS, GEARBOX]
BO_ 330 STEERING_SENSORS: 8 EPS
 SG_ STEER_ANGLE : 7|16@0- (-0.1,0) [-500|500] "deg" EON
 SG_ STEER_ANGLE_RATE : 23|16@0- (-1,0) [-3000|3000] "deg/s" EON
 SG_ STEER_SENSOR_STATUS_1 : 34|1@0+ (1,0) [0|1] "" EON
 SG_ STEER_SENSOR_STATUS_2 : 33|1@0+ (1,0) [0|1] "" EON
 SG_ STEER_SENSOR_STATUS_3 : 32|1@0+ (1,0) [0|1] "" EON
 SG_ STEER_WHEEL_ANGLE : 47|16@0- (-0.1,0) [-500|500] "deg" EON
 SG_ COUNTER : 61|2@0+ (1,0) [0|3] "" EON
 SG_ CHECKSUM : 59|4@0+ (1,0) [0|15] "" EON

BO_ 401 GEARBOX: 8 PCM
 SG_ GEAR_SHIFTER : 5|6@0+ (1,0) [0|63] "" EON
 SG_ BOH : 45|6@0+ (1,0) [0|63] "" XXX
 SG_ GEAR2 : 31|8@0+ (1,0) [0|1] "" XXX
 SG_ GEAR : 39|8@0+ (1,0) [0|255] "" XXX
 SG_ ZEROS_BOH : 47|2@0+ (1,0) [0|3] "" XXX
 SG_ COUNTER : 61|2@0+ (1,0) [0|3] "" EON
 SG_ CHECKSUM : 59|4@0+ (1,0) [0|15] "" EON

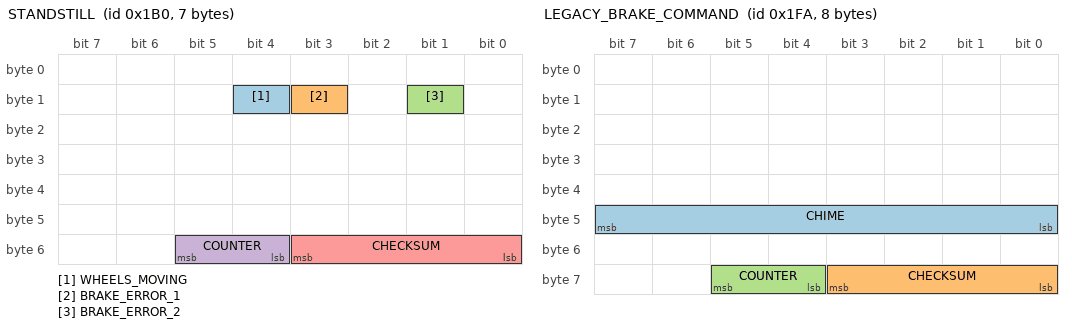
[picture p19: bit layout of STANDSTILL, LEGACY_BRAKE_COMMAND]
BO_ 432 STANDSTILL: 7 VSA
 SG_ WHEELS_MOVING : 12|1@0+ (1,0) [0|1] "" EON
 SG_ BRAKE_ERROR_1 : 11|1@0+ (1,0) [0|1] "" EON
 SG_ BRAKE_ERROR_2 : 9|1@0+ (1,0) [0|1] "" EON
 SG_ COUNTER : 53|2@0+ (1,0) [0|3] "" EON
 SG_ CHECKSUM : 51|4@0+ (1,0) [0|15] "" EON

BO_ 506 LEGACY_BRAKE_COMMAND: 8 ADAS
 SG_ CHIME : 40|8@1+ (1,0) [0|255] "" XXX
 SG_ CHECKSUM : 59|4@0+ (1,0) [0|15] "" XXX
 SG_ COUNTER : 61|2@0+ (1,0) [0|3] "" XXX

BO_ 892 CRUISE_PARAMS: 8 PCM
 SG_ CRUISE_SPEED_OFFSET : 31|8@0- (0.1,0) [-128|127] "kph" EON
 SG_ CHECKSUM : 59|4@0+ (1,0) [0|3] "" EON
 SG_ COUNTER : 61|2@0+ (1,0) [0|15] "" EON

CM_ "AUTOGENERATED FILE, DO NOT EDIT";

CM_ "Imported file _subaru_global.dbc starts here";
CM_ SG_ 64 Throttle_Combo "Throttle Cruise + Pedal";
CM_ SG_ 313 Brake_Lights "Driver or Cruise Brake on";
CM_ SG_ 544 Cruise_Brake_Lights "1 = switch on brake lights";
CM_ SG_ 544 Brake_Pressure "Winds down after cruise disabled. Also can be non-zero when likely preparing for AEB";
CM_ SG_ 544 Signal3 "Usually goes to 2 if AEB_Status is 4";
CM_ SG_ 544 AEB_Status "Occasionally is 4 instead of 8 while Brake_Pressure is non-zero, unsure why";
CM_ SG_ 801 PCB_Off "Pre-Collision Braking off";
CM_ SG_ 801 Brake_Lights "Driver or Cruise brake on";
CM_ SG_ 801 Cruise_State "0 = Normal, 1 = Hold+User Brake, 2 = Ready, 3 = Hold";
CM_ SG_ 801 Far_Distance "1=0-5m, 2=5-10m, 3=10-15m, 4=15-20m, 5=20-25m, 6=25-30m, 7=30-35m, 8=35-40m, 9=40-45m, 10=45-50m, 11=50-55m, 12=55-60m, 13=60-65m, 14=65-70m, 15=75m+";
CM_ SG_ 801 LKAS_State_Msg "1 = LKAS_Off_Sharp_Curve, 2 = Keep_Hands_On_Steering_wheel_disabled, 3 = LKAS_Off, 4 = LKAS_Off_Too_Slow, 5 = LKAS_Off_Too_Fast";
CM_ SG_ 801 Cruise_State_Msg "1 = Cruise_Off_Steep_Slope, 2 = Cruise_lvl1_eco, 3 = Cruise_lvl2_comfort, 4 = Cruise_off_empty_reason, 5 = Cruise_off, 6 = Cruise_Unable_to_set, 7 = Cruise_Unable_to_set_brakes_applied, 8 = Eyesight_not_ready, 9 = Cruise_lvl3_standard, 10 = Cruise_lvl4_dynamic, 11 = Cruise_Unable_to_set_steep_slope";
CM_ SG_ 801 Cruise_Soft_Disable "Eyesight soft disable (eg direct sunlight)";
CM_ SG_ 801 Cruise_Status_Msg "1 = Disabled_Bad_Visibility, 2 = Disabled_Check_Manual";
CM_ SG_ 802 LKAS_ACTIVE "Turns on the full LKAS dash display";
CM_ SG_ 802 LKAS_Alert_Msg "1 = Keep_Hands_On_Wheel, 6 = Pre_Collision_Braking, 7 = Keep_Hands_On_Wheel_Off";
CM_ SG_ 802 LKAS_Alert "1 = FCW_Cont_Beep, 2 = FCW_Repeated_Beep, 3 = Throttle_Management_Activated_Warning, 4 = Throttle_Management_Activated_Alert, 5 = Pre_Collision_Activated_Alert, 8 = Traffic_Light_Ahead, 9 = Apply_Brake_to_Hold Position, 11 = LDW_Right, 12 = LDW_Left, 13 = Stay_Alert, 14 = Lead_Vehicle_Start_Alert, 18 = Keep_Hands_On_Steering_Alert, 24 = Audio_Beep, 25 = Audio_Lead_Car_Change, 26 = Audio_ACC_Disengaged, 27 = Audio_LKAS_disabled, 28 = Audio_Ding_Ding, 30 = Audio_Repeated_Beep";
CM_ SG_ 802 LKAS_Left_Line_Visible "0 = Off, 1 = White, 2 = Green, 3 = Orange";
CM_ SG_ 802 LKAS_Dash_State "0 = Off, 1 = Ready, 2 = Active";
CM_ SG_ 802 LKAS_Right_Line_Visible "0 = Off, 1 = White, 2 = Green, 3 = Orange";
CM_ SG_ 912 UNITS "0 = Metric, 1 = Imperial";
CM_ SG_ 912 ICY_ROAD "1 = DASHLIGHT ON, 2 = WARNING, 3 = OFF";
CM_ "subaru_global_2020_hybrid.dbc starts here";

VAL_ 3 StW_Angl 16383 "SNA" ;
VAL_ 3 StW_AnglSens_Id 2 "MUST" 0 "PSBL" 1 "SELF" ;
VAL_ 3 StW_AnglSens_Stat 2 "ERR" 3 "ERR_INI" 1 "INI" 0 "OK" ;
VAL_ 3 StW_AnglSpd 16383 "SNA" ;
VAL_ 14 StW_AnglHP 16383 "SNA" ;
VAL_ 14 StW_AnglHP_Spd 16383 "SNA" ;
VAL_ 14 StW_AnglHP_Sens_Stat 3 "SNA" 2 "ERR" 1 "INI" 0 "OK" ;
VAL_ 14 StW_AnglHP_Sens_Id 3 "SNA" 2 "KOSTAL" 1 "DELPHI" 0 "TEST" ;
VAL_ 69 SpdCtrlLvr_Stat 32 "DN_1ST" 16 "UP_1ST" 8 "DN_2ND" 4 "UP_2ND" 2 "RWD" 1 "FWD" 0 "IDLE" ;
VAL_ 69 DTR_Dist_Rq 255 "SNA" 200 "ACC_DIST_7" 166 "ACC_DIST_6" 133 "ACC_DIST_5" 100 "ACC_DIST_4" 66 "ACC_DIST_3" 33 "ACC_DIST_2" 0 "ACC_DIST_1" ;
VAL_ 69 TurnIndLvr_Stat 3 "SNA" 2 "RIGHT" 1 "LEFT" 0 "IDLE" ;
VAL_ 69 HiBmLvr_Stat 3 "SNA" 2 "HIBM_FLSH_ON_PSD" 1 "HIBM_ON_PSD" 0 "IDLE" ;
VAL_ 69 WprWashSw_Psd 3 "SNA" 2 "WASH" 1 "TIPWIPE" 0 "NPSD" ;
VAL_ 69 WprWash_R_Sw_Posn_V2 3 "SNA" 2 "WASH" 1 "INTERVAL" 0 "OFF" ;
VAL_ 69 StW_Lvr_Stat 4 "STW_BACK" 3 "STW_FWD" 2 "STW_DOWN" 1 "STW_UP" 0 "NPSD" ;
VAL_ 69 StW_Cond_Psd 3 "SNA" 2 "DOWN" 1 "UP" 0 "NPSD" ;
VAL_ 69 HrnSw_Psd 3 "SNA" 2 "NDEF2" 1 "PSD" 0 "NPSD" ;
VAL_ 69 StW_Sw00_Psd 1 "PRESSED" 0 "NOT_PRESSED_SNA" ;
VAL_ 69 StW_Sw01_Psd 1 "PRESSED" 0 "NOT_PRESSED_SNA" ;
VAL_ 69 StW_Sw03_Psd 1 "PRESSED" 0 "NOT_PRESSED_SNA" ;
VAL_ 69 StW_Sw04_Psd 1 "PRESSED" 0 "NOT_PRESSED_SNA" ;
VAL_ 69 WprSw6Posn 7 "SNA" 6 "STAGE2" 5 "STAGE1" 4 "INTERVAL4" 3 "INTERVAL3" 2 "INTERVAL2" 1 "INTERVAL1" 0 "OFF" ;
VAL_ 257 GTW_epasControlType 0 "WITHOUT" 1 "WITH_ANGLE" 3 "WITH_BOTH" 2 "WITH_TORQUE" ;
VAL_ 109 StW_Sw_Stat3 7 "SNA" 6 "NDEF6" 5 "NDEF5" 4 "NDEF4" 3 "PLUS_MINUS" 2 "MINUS" 1 "PLUS" 0 "NPSD" ;
VAL_ 109 MsgTxmtId 3 "NDEF3" 2 "NDEF2" 1 "SCCM" 0 "EWM" ;
VAL_ 109 TSL_RND_Posn_StW 15 "SNA" 8 "D" 6 "INI" 4 "N_DOWN" 2 "N_UP" 1 "R" 0 "IDLE" ;
VAL_ 109 TSL_P_Psd_StW 3 "SNA" 2 "INI" 1 "PSD" 0 "IDLE" ;
VAL_ 257 GTW_epasEmergencyOn 1 "EMERGENCY_POWER" 0 "NONE" ;
VAL_ 257 GTW_epasLDWEnabled 1 "ALLOWED" 0 "INHIBITED" ;
VAL_ 257 GTW_epasPowerMode 0 "DRIVE_OFF" 1 "DRIVE_ON" 3 "LOAD_SHED" 2 "SHUTTING_DOWN" 15 "SNA" ;
VAL_ 257 GTW_epasTuneRequest 1 "DM_COMFORT" 3 "DM_SPORT" 2 "DM_STANDARD" 0 "FAIL_SAFE_DEFAULT" 4 "RWD_COMFORT" 6 "RWD_SPORT" 5 "RWD_STANDARD" 7 "SNA" ;
VAL_ 264 DI_torqueDriver -4096 "SNA" ;
VAL_ 264 DI_torqueMotor -4096 "SNA" ;
VAL_ 264 DI_soptState 7 "SOPT_TEST_SNA" 4 "SOPT_TEST_NOT_RUN" 3 "SOPT_TEST_PASSED" 2 "SOPT_TEST_FAILED" 1 "SOPT_TEST_IN_PROGRESS" 0 "SOPT_PRE_TEST" ;
VAL_ 264 DI_motorRPM -32768 "SNA" ;
VAL_ 264 DI_pedalPos 255 "SNA" ;
VAL_ 280 DI_torqueEstimate -2048 "SNA" ;
VAL_ 280 DI_gear 7 "DI_GEAR_SNA" 4 "DI_GEAR_D" 3 "DI_GEAR_N" 2 "DI_GEAR_R" 1 "DI_GEAR_P" 0 "DI_GEAR_INVALID" ;
VAL_ 280 DI_brakePedal 1 "Applied" 0 "Not_applied" ;
VAL_ 280 DI_vehicleSpeed 4095 "SNA" ;
VAL_ 280 DI_gearRequest 7 "DI_GEAR_SNA" 4 "DI_GEAR_D" 3 "DI_GEAR_N" 2 "DI_GEAR_R" 1 "DI_GEAR_P" 0 "DI_GEAR_INVALID" ;
VAL_ 280 DI_torqueInterfaceFailure 1 "TORQUE_INTERFACE_FAILED" 0 "TORQUE_INTERFACE_NORMAL" ;
VAL_ 280 DI_brakePedalState 3 "SNA" 2 "INVALID" 1 "ON" 0 "OFF" ;
VAL_ 280 DI_epbParkRequest 1 "Park_requested" 0 "No_request" ;
VAL_ 280 DI_epbInterfaceReady 1 "EPB_INTERFACE_READY" 0 "EPB_INTERFACE_NOT_READY" ;
VAL_ 309 ESP_absBrakeEvent 1 "ACTIVE" 0 "NOT_ACTIVE" ;
VAL_ 309 ESP_brakeDiscWipingActive 1 "ACTIVE" 0 "INACTIVE" ;
VAL_ 309 ESP_brakeLamp 0 "OFF" 1 "ON" ;
VAL_ 309 ESP_espFaultLamp 0 "OFF" 1 "ON" ;
VAL_ 309 ESP_espLampFlash 1 "FLASH" 0 "OFF" ;
VAL_ 309 ESP_hillStartAssistActive 1 "ACTIVE" 0 "INACTIVE" 2 "NOT_AVAILABLE" 3 "SNA" ;
VAL_ 309 ESP_absFaultLamp 0 "OFF" 1 "ON" ;
VAL_ 309 ESP_espOffLamp 0 "OFF" 1 "ON" ;
VAL_ 309 ESP_stabilityControlSts 2 "ENGAGED" 3 "FAULTED" 5 "INIT" 4 "NOT_CONFIGURED" 0 "OFF" 1 "ON" ;
VAL_ 309 ESP_tcLampFlash 1 "FLASH" 0 "OFF" ;
VAL_ 568 UI_mapSpeedLimit 31 "SNA" 30 "UNLIMITED" 29 "LESS_OR_EQ_160" 28 "LESS_OR_EQ_150" 27 "LESS_OR_EQ_140" 26 "LESS_OR_EQ_130" 25 "LESS_OR_EQ_120" 24 "LESS_OR_EQ_115" 23 "LESS_OR_EQ_110" 22 "LESS_OR_EQ_105" 21 "LESS_OR_EQ_100" 20 "LESS_OR_EQ_95" 19 "LESS_OR_EQ_90" 18 "LESS_OR_EQ_85" 17 "LESS_OR_EQ_80" 16 "LESS_OR_EQ_75" 15 "LESS_OR_EQ_70" 14 "LESS_OR_EQ_65" 13 "LESS_OR_EQ_60" 12 "LESS_OR_EQ_55" 11 "LESS_OR_EQ_50" 10 "LESS_OR_EQ_45" 9 "LESS_OR_EQ_40" 8 "LESS_OR_EQ_35" 7 "LESS_OR_EQ_30" 6 "LESS_OR_EQ_25" 5 "LESS_OR_EQ_20" 4 "LESS_OR_EQ_15" 3 "LESS_OR_EQ_10" 2 "LESS_OR_EQ_7" 1 "LESS_OR_EQ_5" 0 "UNKNOWN" ;
VAL_ 569 DAS_leftLineUsage 3 "BLACKLISTED" 2 "FUSED" 1 "AVAILABLE" 0 "REJECTED_UNAVAILABLE" ;
VAL_ 569 DAS_rightLineUsage 3 "BLACKLISTED" 2 "FUSED" 1 "AVAILABLE" 0 "REJECTED_UNAVAILABLE" ;
VAL_ 569 DAS_leftFork 3 "LEFT_FORK_UNAVAILABLE" 2 "LEFT_FORK_SELECTED" 1 "LEFT_FORK_AVAILABLE" 0 "LEFT_FORK_NONE" ;
VAL_ 569 DAS_rightFork 3 "RIGHT_FORK_UNAVAILABLE" 2 "RIGHT_FORK_SELECTED" 1 "RIGHT_FORK_AVAILABLE" 0 "RIGHT_FORK_NONE" ;
VAL_ 521 DAS_locMode 3 "DAS_LOC_DRIVERLESS" 2 "DAS_LOC_RESTRICTED" 1 "DAS_LOC_NORMAL" 0 "DAS_LOC_OFF" ;
VAL_ 521 DAS_locState 7 "DAS_LOC_FAULT_SNA" 6 "DAS_LOC_AEB_ACTIVE" 2 "DAS_LOC_CANCEL_SILENT" 1 "DAS_LOC_CANCEL_GENERIC" 0 "DAS_LOC_HEALTHY" ;
VAL_ 521 DAS_locRequest 4 "DAS_RQ_PARK" 3 "DAS_RQ_HOLD" 2 "DAS_RQ_BACKWARD" 1 "DAS_RQ_FORWARD" 0 "DAS_RQ_IDLE" ;
VAL_ 521 DAS_locJerkMin 255 "SNA" ;
VAL_ 521 DAS_locJerkMax 255 "SNA" ;
VAL_ 521 DAS_locSpeed 2047 "SNA" ;
VAL_ 521 DAS_locAccelMin 511 "SNA" ;
VAL_ 521 DAS_locAccelMax 511 "SNA" ;
VAL_ 522 driverBrakeStatus 2 "APPLIED" 1 "NOT_APPLIED" ;
VAL_ 760 UI_mapSpeedLimitUnits 1 "KPH" 0 "MPH" ;
VAL_ 760 UI_userSpeedOffsetUnits 1 "KPH" 0 "MPH" ;
VAL_ 643 AirTemp_Insd 255 "SNA" ;
VAL_ 643 AirTemp_Outsd 254 "INIT" 255 "SNA" ;
VAL_ 643 Bckl_Sw_RL_Stat_SAM_R 2 "FLT" 1 "NOT" 0 "OK" 3 "SNA" ;
VAL_ 643 Bckl_Sw_RM_Stat_SAM_R 2 "FLT" 1 "NOT" 0 "OK" 3 "SNA" ;
VAL_ 643 Bckl_Sw_RR_Stat_SAM_R 2 "FLT" 1 "NOT" 0 "OK" 3 "SNA" ;
VAL_ 643 DL_RLtch_Stat 1 "CLS" 0 "NDEF0" 2 "OPN" 3 "SNA" ;
VAL_ 643 DrRLtch_FL_Stat 1 "CLS" 0 "NDEF0" 2 "OPN" 3 "SNA" ;
VAL_ 643 DrRLtch_FR_Stat 1 "CLS" 0 "NDEF0" 2 "OPN" 3 "SNA" ;
VAL_ 643 DrRLtch_RL_Stat 1 "CLS" 0 "NDEF0" 2 "OPN" 3 "SNA" ;
VAL_ 643 DrRLtch_RR_Stat 1 "CLS" 0 "NDEF0" 2 "OPN" 3 "SNA" ;
VAL_ 643 EngHd_Stat 1 "CLS" 0 "NDEF0" 2 "OPN" 3 "SNA" ;
VAL_ 643 LgtSens_Night 0 "DAY" 1 "NIGHT" ;
VAL_ 643 MPkBrk_Stat 1 "ENGG" 0 "RELS" ;
VAL_ 643 RevGr_Engg 0 "DISENGG" 1 "ENGG" 2 "NDEF2" 3 "SNA" ;
VAL_ 643 StW_Cond_Stat 3 "BLINK" 1 "NDEF1" 0 "OFF" 2 "ON" ;
VAL_ 643 Trlr_Stat 2 "NDEF2" 0 "NONE" 1 "OK" 3 "SNA" ;
VAL_ 697 DAS_setSpeed 4095 "SNA" ;
VAL_ 697 DAS_accState 15 "FAULT_SNA" 13 "ACC_CANCEL_GENERIC_SILENT" 11 "APC_SELFPARK_START" 10 "APC_UNPARK_COMPLETE" 9 "APC_PAUSE" 8 "APC_ABORT" 7 "APC_COMPLETE" 6 "APC_FORWARD" 5 "APC_BACKWARD" 4 "ACC_ON" 3 "ACC_HOLD" 0 "ACC_CANCEL_GENERIC" ;
VAL_ 697 DAS_aebEvent 3 "AEB_SNA" 2 "AEB_FAULT" 1 "AEB_ACTIVE" 0 "AEB_NOT_ACTIVE" ;
VAL_ 697 DAS_jerkMin 511 "SNA" ;
VAL_ 697 DAS_jerkMax 255 "SNA" ;
VAL_ 697 DAS_accelMin 511 "SNA" ;
VAL_ 697 DAS_accelMax 511 "SNA" ;
VAL_ 792 BOOT_STATE 2 "Init" 3 "SNA" 0 "closed" 1 "open" ;
VAL_ 792 CERRD 1 "CAN error detect" 0 "no Can error detected" ;
VAL_ 792 DAY 1 "Init" 0 "SNA" ;
VAL_ 792 DOOR_STATE_FL 2 "Init" 3 "SNA" 0 "closed" 1 "open" ;
VAL_ 792 DOOR_STATE_FR 2 "Init" 3 "SNA" 0 "closed" 1 "open" ;
VAL_ 792 DOOR_STATE_FrontTrunk 2 "Init" 3 "SNA" 0 "closed" 1 "open" ;
VAL_ 792 DOOR_STATE_RL 2 "Init" 3 "SNA" 0 "closed" 1 "open" ;
VAL_ 792 DOOR_STATE_RR 2 "Init" 3 "SNA" 0 "closed" 1 "open" ;
VAL_ 792 GTW_updateInProgress 1 "IN_PROGRESS" 2 "IN_PROGRESS_NOT_USED" 3 "IN_PROGRESS_SNA" 0 "NOT_IN_PROGRESS" ;
VAL_ 792 Hour 30 "Init" 31 "SNA" ;
VAL_ 792 MCU_factoryMode 1 "FACTORY_MODE" 0 "NORMAL_MODE" ;
VAL_ 792 MCU_transportModeOn 0 "NORMAL_MODE" ;
VAL_ 792 MINUTE 62 "Init" 63 "SNA" ;
VAL_ 792 MONTH 1 "Init" 15 "SNA" ;
VAL_ 792 SECOND 62 "Init" 63 "SNA" ;
VAL_ 792 YEAR 126 "Init" 127 "SNA" ;
VAL_ 872 DI_aebState 2 "ENABLED" 4 "FAULT" 7 "SNA" 1 "STANDBY" 3 "STANDSTILL" 0 "UNAVAILABLE" ;
VAL_ 872 DI_analogSpeed 4095 "SNA" ;
VAL_ 872 DI_cruiseState 2 "ENABLED" 5 "FAULT" 0 "OFF" 4 "OVERRIDE" 7 "PRE_CANCEL" 6 "PRE_FAULT" 1 "STANDBY" 3 "STANDSTILL" ;
VAL_ 872 DI_digitalSpeed 255 "SNA" ;
VAL_ 872 DI_immobilizerState 2 "AUTHENTICATING" 3 "DISARMED" 6 "FAULT" 4 "IDLE" 0 "INIT_SNA" 1 "REQUEST" 5 "RESET" ;
VAL_ 872 DI_speedUnits 1 "KPH" 0 "MPH" ;
VAL_ 872 DI_state 3 "ABORT" 4 "ENABLE" 2 "FAULT" 1 "STANDBY" 0 "UNAVAILABLE" ;
VAL_ 872 DI_systemState 3 "ABORT" 4 "ENABLE" 2 "FAULT" 1 "STANDBY" 0 "UNAVAILABLE" ;
VAL_ 872 DI_vehicleHoldState 2 "BLEND_IN" 4 "BLEND_OUT" 6 "FAULT" 7 "INIT" 5 "PARK" 1 "STANDBY" 3 "STANDSTILL" 0 "UNAVAILABLE" ;
VAL_ 880 EPAS_currentTuneMode 1 "DM_COMFORT" 3 "DM_SPORT" 2 "DM_STANDARD" 0 "FAIL_SAFE_DEFAULT" 4 "RWD_COMFORT" 6 "RWD_SPORT" 5 "RWD_STANDARD" 7 "UNAVAILABLE" ;
VAL_ 880 EPAS_eacErrorCode 14 "EAC_ERROR_EPB_INHIBIT" 3 "EAC_ERROR_HANDS_ON" 7 "EAC_ERROR_HIGH_ANGLE_RATE_REQ" 9 "EAC_ERROR_HIGH_ANGLE_RATE_SAFETY" 6 "EAC_ERROR_HIGH_ANGLE_REQ" 8 "EAC_ERROR_HIGH_ANGLE_SAFETY" 10 "EAC_ERROR_HIGH_MMOT_SAFETY" 11 "EAC_ERROR_HIGH_TORSION_SAFETY" 0 "EAC_ERROR_IDLE" 12 "EAC_ERROR_LOW_ASSIST" 2 "EAC_ERROR_MAX_SPEED" 1 "EAC_ERROR_MIN_SPEED" 13 "EAC_ERROR_PINION_VEL_DIFF" 4 "EAC_ERROR_TMP_FAULT" 5 "EAR_ERROR_MAX_STEER_DELTA" 15 "SNA" ;
VAL_ 880 EPAS_eacStatus 2 "EAC_ACTIVE" 1 "EAC_AVAILABLE" 3 "EAC_FAULT" 0 "EAC_INHIBITED" 4 "SNA" ;
VAL_ 880 EPAS_handsOnLevel 0 "0" 1 "1" 2 "2" 3 "3" ;
VAL_ 880 EPAS_steeringFault 1 "FAULT" 0 "NO_FAULT" ;
VAL_ 880 EPAS_steeringRackForce 1022 "NOT_IN_SPEC" 1023 "SNA" ;
VAL_ 880 EPAS_steeringReduced 0 "NORMAL_ASSIST" 1 "REDUCED_ASSIST" ;
VAL_ 880 EPAS_torsionBarTorque 0 "SEE_SPECIFICATION" 4095 "SNA" 4094 "UNDEFINABLE_DATA" ;
VAL_ 904 MCU_clusterReadyForDrive 0 "NO_SNA" 1 "YES" ;
VAL_ 905 DAS_accSpeedLimit 1023 "SNA" 0 "NONE" ;
VAL_ 905 DAS_pmmObstacleSeverity 7 "PMM_SNA" 6 "PMM_ACCEL_LIMIT" 5 "PMM_CRASH_FRONT" 4 "PMM_CRASH_REAR" 3 "PMM_BRAKE_REQUEST" 2 "PMM_IMMINENT_FRONT" 1 "PMM_IMMINENT_REAR" 0 "PMM_NONE" ;
VAL_ 905 DAS_pmmLoggingRequest 1 "TRUE" 0 "FALSE" ;
VAL_ 905 DAS_activationFailureStatus 2 "LC_ACTIVATION_FAILED_2" 1 "LC_ACTIVATION_FAILED_1" 0 "LC_ACTIVATION_IDLE" ;
VAL_ 905 DAS_pmmUltrasonicsFaultReason 4 "PMM_ULTRASONICS_INVALID_MIA" 3 "PMM_ULTRASONICS_BLOCKED_BOTH" 2 "PMM_ULTRASONICS_BLOCKED_REAR" 1 "PMM_ULTRASONICS_BLOCKED_FRONT" 0 "PMM_ULTRASONICS_NO_FAULT" ;
VAL_ 905 DAS_pmmRadarFaultReason 2 "PMM_RADAR_INVALID_MIA" 1 "PMM_RADAR_BLOCKED_FRONT" 0 "PMM_RADAR_NO_FAULT" ;
VAL_ 905 DAS_pmmSysFaultReason 7 "PMM_FAULT_BRAKE_PEDAL_INHIBIT" 6 "PMM_FAULT_ROAD_TYPE" 5 "PMM_FAULT_DISABLED_BY_USER" 4 "PMM_FAULT_STEERING_ANGLE_RATE" 3 "PMM_FAULT_DI_FAULT" 2 "PMM_FAULT_SPEED" 1 "PMM_FAULT_DAS_DISABLED" 0 "PMM_FAULT_NONE" ;
VAL_ 905 DAS_pmmCameraFaultReason 2 "PMM_CAMERA_INVALID_MIA" 1 "PMM_CAMERA_BLOCKED_FRONT" 0 "PMM_CAMERA_NO_FAULT" ;
VAL_ 905 DAS_ACC_report 24 "ACC_REPORT_BEHAVIOR_REPORT" 23 "ACC_REPORT_CAMERA_ONLY" 22 "ACC_REPORT_RADAR_OBJ_FIVE" 21 "ACC_REPORT_CIPV_CUTTING_OUT" 20 "ACC_REPORT_MCVLR_IN_PATH" 19 "ACC_REPORT_MCVLR_DPP" 18 "ACC_REPORT_FLEET_SPEEDS" 17 "ACC_REPORT_TARGET_MCP" 16 "ACC_REPORT_RADAR_OBJ_TWO" 15 "ACC_REPORT_RADAR_OBJ_ONE" 14 "ACC_REPORT_LC_EXTERNAL_STATE_ACTIVE_RESTRICTED" 13 "ACC_REPORT_LC_EXTERNAL_STATE_ABORTED" 12 "ACC_REPORT_LC_EXTERNAL_STATE_ABORTING" 11 "ACC_REPORT_LC_HANDS_ON_REQD_STRUCK_OUT" 10 "ACC_REPORT_CSA" 9 "ACC_REPORT_TARGET_TYPE_FAULT" 8 "ACC_REPORT_TARGET_TYPE_IPSO" 7 "ACC_REPORT_TARGET_TYPE_TRAFFIC_LIGHT" 6 "ACC_REPORT_TARGET_TYPE_STOP_SIGN" 5 "ACC_REPORT_TARGET_CUTIN" 4 "ACC_REPORT_TARGET_MCVR" 3 "ACC_REPORT_TARGET_MCVL" 2 "ACC_REPORT_TARGET_IN_FRONT_OF_CIPV" 1 "ACC_REPORT_TARGET_CIPV" 0 "ACC_REPORT_TARGET_NONE" ;
VAL_ 905 DAS_lssState 7 "LSS_STATE_OFF" 6 "LSS_STATE_ABORT" 5 "LSS_STATE_BLINDSPOT" 4 "LSS_STATE_MONITOR" 3 "LSS_STATE_ELK" 2 "LSS_STATE_LKA" 1 "LSS_STATE_LDW" 0 "LSS_STATE_FAULT" ;
VAL_ 905 DAS_radarTelemetry 2 "RADAR_TELEMETRY_URGENT" 1 "RADAR_TELEMETRY_NORMAL" 0 "RADAR_TELEMETRY_IDLE" ;
VAL_ 905 DAS_robState 3 "ROB_STATE_MAPLESS" 2 "ROB_STATE_ACTIVE" 1 "ROB_STATE_MEASURE" 0 "ROB_STATE_INHIBITED" ;
VAL_ 905 DAS_driverInteractionLevel 2 "CONTINUED_DRIVER_NOT_INTERACTING" 1 "DRIVER_NOT_INTERACTING" 0 "DRIVER_INTERACTING" ;
VAL_ 905 DAS_ppOffsetDesiredRamp 128 "PP_NO_OFFSET" ;
VAL_ 905 DAS_longCollisionWarning 15 "FCM_LONG_COLLISION_WARNING_SNA" 12 "FCM_LONG_COLLISION_WARNING_VEHICLE_CIPV2" 11 "FCM_LONG_COLLISION_WARNING_VEHICLE_MCVR2" 10 "FCM_LONG_COLLISION_WARNING_VEHICLE_MCVR" 9 "FCM_LONG_COLLISION_WARNING_VEHICLE_MCVL2" 8 "FCM_LONG_COLLISION_WARNING_VEHICLE_MCVL" 7 "FCM_LONG_COLLISION_WARNING_VEHICLE_CUTIN" 6 "FCM_LONG_COLLISION_WARNING_VEHICLE_CIPV" 5 "FCM_LONG_COLLISION_WARNING_TFL_STOPLINE" 4 "FCM_LONG_COLLISION_WARNING_STOPSIGN_STOPLINE" 3 "FCM_LONG_COLLISION_WARNING_IPSO" 2 "FCM_LONG_COLLISION_WARNING_PEDESTRIAN" 1 "FCM_LONG_COLLISION_WARNING_VEHICLE_UNKNOWN" 0 "FCM_LONG_COLLISION_WARNING_NONE" ;
VAL_ 921 autopilotStatus 5 "ACTIVE_NAVIGATE_ON_AUTOPILOT" 4 "ACTIVE_2" 3 "ACTIVE_1" 2 "AVAILABLE" 1 "UNAVAILABLE" 0 "DISABLED" ;
VAL_ 921 DAS_blindSpotRearLeft 3 "SNA" 2 "WARNING_LEVEL_2" 1 "WARNING_LEVEL_1" 0 "NO_WARNING" ;
VAL_ 921 DAS_blindSpotRearRight 3 "SNA" 2 "WARNING_LEVEL_2" 1 "WARNING_LEVEL_1" 0 "NO_WARNING" ;
VAL_ 921 DAS_fusedSpeedLimit 31 "NONE" 0 "UNKNOWN_SNA" ;
VAL_ 921 DAS_suppressSpeedWarning 1 "Suppress_Speed_Warning" 0 "Do_Not_Suppress" ;
VAL_ 921 DAS_visionOnlySpeedLimit 31 "NONE" 0 "UNKNOWN_SNA" ;
VAL_ 921 DAS_heaterState 1 "HEATER_ON" 0 "HEATER_OFF_SNA" ;
VAL_ 921 DAS_forwardCollisionWarning 3 "SNA" 1 "FORWARD_COLLISION_WARNING" 0 "NONE" ;
VAL_ 921 DAS_autoparkReady 1 "AUTOPARK_READY" 0 "AUTOPARK_UNAVAILABLE" ;
VAL_ 921 DAS_sideCollisionAvoid 3 "SNA" 2 "AVOID_RIGHT" 1 "AVOID_LEFT" 0 "NONE" ;
VAL_ 921 DAS_sideCollisionWarning 3 "WARN_LEFT_RIGHT" 2 "WARN_RIGHT" 1 "WARN_LEFT" 0 "NONE" ;
VAL_ 921 DAS_sideCollisionInhibit 1 "INHIBIT" 0 "NO_INHIBIT" ;
VAL_ 921 DAS_csaState 3 "CSA_EXTERNAL_STATE_HOLD" 2 "CSA_EXTERNAL_STATE_ENABLE" 1 "CSA_EXTERNAL_STATE_AVAILABLE" 0 "CSA_EXTERNAL_STATE_UNAVAILABLE" ;
VAL_ 921 DAS_laneDepartureWarning 5 "SNA" 4 "RIGHT_WARNING_SEVERE" 3 "LEFT_WARNING_SEVERE" 2 "RIGHT_WARNING" 1 "LEFT_WARNING" 0 "NONE" ;
VAL_ 921 DAS_fleetSpeedState 3 "FLEETSPEED_HOLD" 2 "FLEETSPEED_ACTIVE" 1 "FLEETSPEED_AVAILABLE" 0 "FLEETSPEED_UNAVAILABLE" ;
VAL_ 921 DAS_autopilotHandsOnState 15 "LC_HANDS_ON_SNA" 8 "LC_HANDS_ON_SUSPENDED" 7 "LC_HANDS_ON_REQD_STRUCK_OUT" 5 "LC_HANDS_ON_REQD_CHIME_2" 4 "LC_HANDS_ON_REQD_CHIME_1" 3 "LC_HANDS_ON_REQD_VISUAL" 2 "LC_HANDS_ON_REQD_NOT_DETECTED" 1 "LC_HANDS_ON_REQD_DETECTED" 0 "LC_HANDS_ON_NOT_REQD" ;
VAL_ 921 DAS_autoLaneChangeState 31 "ALC_SNA" 30 "ALC_ABORT_MISSION_PLAN_INVALID" 29 "ALC_ABORT_TIMEOUT" 28 "ALC_WAITING_HANDS_ON" 27 "ALC_BLOCKED_LANE_TYPE_R" 26 "ALC_BLOCKED_LANE_TYPE_L" 25 "ALC_BLOCKED_VEH_TTC_AND_USS_R" 24 "ALC_BLOCKED_VEH_TTC_R" 23 "ALC_BLOCKED_VEH_TTC_AND_USS_L" 22 "ALC_BLOCKED_VEH_TTC_L" 21 "ALC_UNAVAILABLE_SOLID_LANE_LINE" 20 "ALC_ABORT_OTHER_REASON" 19 "ALC_ABORT_BLINKER_TURNED_OFF" 18 "ALC_ABORT_LC_HEALTH_BAD" 17 "ALC_ABORT_POOR_VIEW_RANGE" 16 "ALC_ABORT_SIDE_OBSTACLE_PRESENT_R" 15 "ALC_ABORT_SIDE_OBSTACLE_PRESENT_L" 14 "ALC_WAITING_FOR_FWD_OBST_TO_PASS_R" 13 "ALC_WAITING_FOR_FWD_OBST_TO_PASS_L" 12 "ALC_WAITING_FOR_SIDE_OBST_TO_PASS_R" 11 "ALC_WAITING_FOR_SIDE_OBST_TO_PASS_L" 10 "ALC_IN_PROGRESS_R" 9 "ALC_IN_PROGRESS_L" 8 "ALC_AVAILABLE_BOTH" 7 "ALC_AVAILABLE_ONLY_R" 6 "ALC_AVAILABLE_ONLY_L" 5 "ALC_UNAVAILABLE_VEHICLE_SPEED" 4 "ALC_UNAVAILABLE_EXITING_HIGHWAY" 3 "ALC_UNAVAILABLE_TP_FOLLOW" 2 "ALC_UNAVAILABLE_SONICS_INVALID" 1 "ALC_UNAVAILABLE_NO_LANES" 0 "ALC_UNAVAILABLE_DISABLED" ;
VAL_ 1001 DAS_headlightRequest 3 "DAS_HEADLIGHT_REQUEST_INVALID" 1 "DAS_HEADLIGHT_REQUEST_ON" 0 "DAS_HEADLIGHT_REQUEST_OFF" ;
VAL_ 1001 DAS_hazardLightRequest 3 "DAS_REQUEST_HAZARDS_SNA" 2 "DAS_REQUEST_HAZARDS_UNUSED" 1 "DAS_REQUEST_HAZARDS_ON" 0 "DAS_REQUEST_HAZARDS_OFF" ;
VAL_ 1001 DAS_wiperSpeed 15 "DAS_WIPER_SPEED_INVALID" 14 "DAS_WIPER_SPEED_14" 13 "DAS_WIPER_SPEED_13" 12 "DAS_WIPER_SPEED_12" 11 "DAS_WIPER_SPEED_11" 10 "DAS_WIPER_SPEED_10" 9 "DAS_WIPER_SPEED_9" 8 "DAS_WIPER_SPEED_8" 7 "DAS_WIPER_SPEED_7" 6 "DAS_WIPER_SPEED_6" 5 "DAS_WIPER_SPEED_5" 4 "DAS_WIPER_SPEED_4" 3 "DAS_WIPER_SPEED_3" 2 "DAS_WIPER_SPEED_2" 1 "DAS_WIPER_SPEED_1" 0 "DAS_WIPER_SPEED_OFF" ;
VAL_ 1001 DAS_turnIndicatorRequest 3 "DAS_TURN_INDICATOR_CANCEL" 2 "DAS_TURN_INDICATOR_RIGHT" 1 "DAS_TURN_INDICATOR_LEFT" 0 "DAS_TURN_INDICATOR_NONE" ;
VAL_ 1001 DAS_highLowBeamDecision 3 "DAS_HIGH_BEAM_SNA" 2 "DAS_HIGH_BEAM_ON" 1 "DAS_HIGH_BEAM_OFF" 0 "DAS_HIGH_BEAM_UNDECIDED" ;
VAL_ 1001 DAS_highLowBeamOffReason 5 "HIGH_BEAM_OFF_REASON_SNA" 4 "HIGH_BEAM_OFF_REASON_HEAD_LIGHT" 3 "HIGH_BEAM_OFF_REASON_AMBIENT_LIGHT" 2 "HIGH_BEAM_OFF_REASON_MOVING_RADAR_TARGET" 1 "HIGH_BEAM_OFF_REASON_MOVING_VISION_TARGET" 0 "HIGH_BEAM_ON" ;
VAL_ 1001 DAS_turnIndicatorRequestReason 6 "DAS_ACTIVE_COMMANDED_LANE_CHANGE" 5 "DAS_CANCEL_FORK" 4 "DAS_CANCEL_LANE_CHANGE" 3 "DAS_ACTIVE_FORK" 2 "DAS_ACTIVE_SPEED_LANE_CHANGE" 1 "DAS_ACTIVE_NAV_LANE_CHANGE" 0 "DAS_NONE" ;
VAL_ 1160 DAS_steeringAngleRequest 16384 "ZERO_ANGLE" ;
VAL_ 1160 DAS_steeringControlType 1 "ANGLE_CONTROL" 3 "DISABLED" 0 "NONE" 2 "RESERVED" ;
